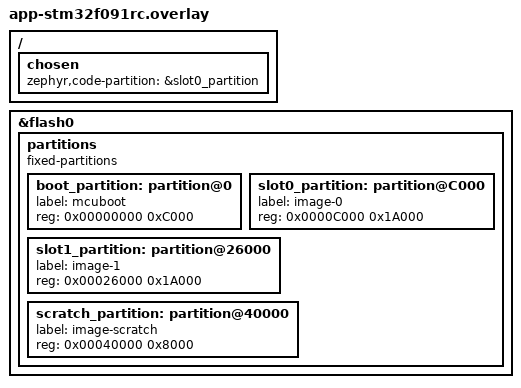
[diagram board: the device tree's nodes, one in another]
/ {
    chosen {
        zephyr,code-partition = &slot0_partition;
    };
};

&flash0 {
    partitions {
        compatible = "fixed-partitions";
        #address-cells = <1>;
        #size-cells = <1>;

        boot_partition: partition@0 {
            label = "mcuboot";
            reg = <0x00000000 0xC000>;  // Increased to 48K (0xC000)
        };

        slot0_partition: partition@C000 {
            label = "image-0";
            reg = <0x0000C000 0x1A000>;  // Adjusted start, size remains 104K
        };

        slot1_partition: partition@26000 {
            label = "image-1";
            reg = <0x00026000 0x1A000>;  // Adjusted start, size remains 104K
        };

        // Optional: Add a scratch partition if you need swap-based updates
        scratch_partition: partition@40000 {
            label = "image-scratch";
            reg = <0x00040000 0x8000>;  // 32K for scratch
        };
    };
};
